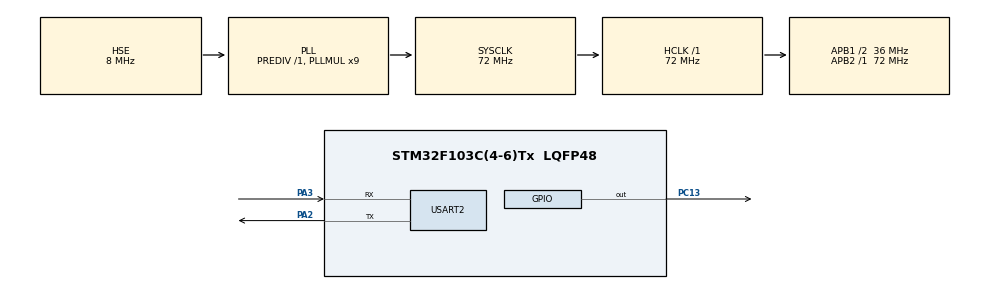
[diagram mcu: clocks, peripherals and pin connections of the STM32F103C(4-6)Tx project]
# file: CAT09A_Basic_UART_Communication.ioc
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Mcu.Family=STM32F1
Mcu.Name=STM32F103C(4-6)Tx
Mcu.Package=LQFP48
NVIC.PriorityGroup=NVIC_PRIORITYGROUP_4
PA13.Mode=Serial_Wire
PA13.Signal=SYS_JTMS-SWDIO
PA14.Mode=Serial_Wire
PA14.Signal=SYS_JTCK-SWCLK
PA2.Mode=Asynchronous
PA2.Signal=USART2_TX
PA3.Mode=Asynchronous
PA3.Signal=USART2_RX
PC13-TAMPER-RTC.Signal=GPIO_Output
PD0-OSC_IN.Mode=HSE-External-Oscillator
PD0-OSC_IN.Signal=RCC_OSC_IN
PD1-OSC_OUT.Mode=HSE-External-Oscillator
PD1-OSC_OUT.Signal=RCC_OSC_OUT
ProjectManager.HeapSize=0x200
ProjectManager.StackSize=0x400
ProjectManager.TargetToolchain=STM32CubeIDE
RCC.AHBFreq_Value=72000000
RCC.APB1CLKDivider=RCC_HCLK_DIV2
RCC.APB1Freq_Value=36000000
RCC.APB1TimFreq_Value=72000000
RCC.APB2Freq_Value=72000000
RCC.APB2TimFreq_Value=72000000
RCC.HCLKFreq_Value=72000000
RCC.PLLMUL=RCC_PLL_MUL9
RCC.PLLSourceVirtual=RCC_PLLSOURCE_HSE
RCC.SYSCLKFreq_VALUE=72000000
RCC.SYSCLKSource=RCC_SYSCLKSOURCE_PLLCLK
RCC.USBFreq_Value=72000000
USART2.VirtualMode=VM_ASYNC
board=custom

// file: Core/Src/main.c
/* USER CODE BEGIN Header */
/**
  ******************************************************************************
  * @file           : main.c
  * @brief          : CAT 9 - Task 9A : Basic UART communication (USART2, 115200-8-N-1)
  *                    Echoes every received character; sends 'A' once per second while idle.
  ******************************************************************************
  * @attention
  *
  * Copyright (c) 2026 STMicroelectronics.
  * All rights reserved.
  *
  * This software is licensed under terms that can be found in the LICENSE file
  * in the root directory of this software component.
  * If no LICENSE file comes with this software, it is provided AS-IS.
  *
  ******************************************************************************
  */
/* USER CODE END Header */
#include "main.h"

/* USER CODE BEGIN Includes */
#include <string.h>
/* USER CODE END Includes */

/* USER CODE BEGIN PD */
#define PC_UART          (&huart2)    /* USART2: PA2 = TX, PA3 = RX, 115200-8-N-1 */
#define IDLE_CHAR_MS     1000U        /* send 'A' after 1 s without input         */
/* USER CODE END PD */

UART_HandleTypeDef huart2;

/* USER CODE BEGIN PV */
static uint32_t last_activity_ms = 0;
static uint32_t chars_echoed     = 0;
/* USER CODE END PV */

void SystemClock_Config(void);
static void MX_GPIO_Init(void);
static void MX_USART2_UART_Init(void);

/* USER CODE BEGIN 0 */
static void uart_send_str(const char *s)
{
  HAL_UART_Transmit(PC_UART, (uint8_t *)s, (uint16_t)strlen(s), HAL_MAX_DELAY);
}

static void uart_send_char(uint8_t c)
{
  HAL_UART_Transmit(PC_UART, &c, 1, HAL_MAX_DELAY);
}
/* USER CODE END 0 */

int main(void)
{

  /* MCU Configuration--------------------------------------------------------*/

  /* Reset of all peripherals, Initializes the Flash interface and the Systick. */
  HAL_Init();

  /* Configure the system clock */
  SystemClock_Config();

  /* Initialize all configured peripherals */
  MX_GPIO_Init();
  MX_USART2_UART_Init();
  /* USER CODE BEGIN 2 */
  uart_send_str("\r\nCAT9A - STM32 Blue Pill UART ready (115200-8-N-1)\r\n");
  uart_send_str("Type anything: it is echoed. Idle for 1 s -> 'A' is sent.\r\n");
  last_activity_ms = HAL_GetTick();
  /* USER CODE END 2 */

  /* Infinite loop */
  while (1)
  {

    /* USER CODE BEGIN 3 */
    uint8_t rx;

    /* Receive and echo: short 10 ms timeout keeps the loop responsive */
    if (HAL_UART_Receive(PC_UART, &rx, 1, 10) == HAL_OK)
    {
      uart_send_char(rx);
      if (rx == '\r')
        uart_send_char('\n');        /* PuTTY sends only CR on Enter */
      chars_echoed++;
      last_activity_ms = HAL_GetTick();
    }
    /* Transmit a character: nothing received for 1 s -> send 'A' */
    else if ((HAL_GetTick() - last_activity_ms) >= IDLE_CHAR_MS)
    {
      uart_send_char('A');
      last_activity_ms = HAL_GetTick();
    }
  }
  /* USER CODE END 3 */
}

void SystemClock_Config(void)
{
  RCC_OscInitTypeDef RCC_OscInitStruct = {0};
  RCC_ClkInitTypeDef RCC_ClkInitStruct = {0};

  /** Initializes the RCC Oscillators according to the specified parameters
  * in the RCC_OscInitTypeDef structure.
  */
  RCC_OscInitStruct.OscillatorType = RCC_OSCILLATORTYPE_HSE;
  RCC_OscInitStruct.HSEState = RCC_HSE_ON;
  RCC_OscInitStruct.HSEPredivValue = RCC_HSE_PREDIV_DIV1;
  RCC_OscInitStruct.HSIState = RCC_HSI_ON;
  RCC_OscInitStruct.PLL.PLLState = RCC_PLL_ON;
  RCC_OscInitStruct.PLL.PLLSource = RCC_PLLSOURCE_HSE;
  RCC_OscInitStruct.PLL.PLLMUL = RCC_PLL_MUL9;
  if (HAL_RCC_OscConfig(&RCC_OscInitStruct) != HAL_OK)
  {
    Error_Handler();
  }

  /** Initializes the CPU, AHB and APB buses clocks
  */
  RCC_ClkInitStruct.ClockType = RCC_CLOCKTYPE_HCLK|RCC_CLOCKTYPE_SYSCLK
                              |RCC_CLOCKTYPE_PCLK1|RCC_CLOCKTYPE_PCLK2;
  RCC_ClkInitStruct.SYSCLKSource = RCC_SYSCLKSOURCE_PLLCLK;
  RCC_ClkInitStruct.AHBCLKDivider = RCC_SYSCLK_DIV1;
  RCC_ClkInitStruct.APB1CLKDivider = RCC_HCLK_DIV2;
  RCC_ClkInitStruct.APB2CLKDivider = RCC_HCLK_DIV1;

  if (HAL_RCC_ClockConfig(&RCC_ClkInitStruct, FLASH_LATENCY_2) != HAL_OK)
  {
    Error_Handler();
  }
}

static void MX_USART2_UART_Init(void)
{

  huart2.Instance = USART2;
  huart2.Init.BaudRate = 115200;
  huart2.Init.WordLength = UART_WORDLENGTH_8B;
  huart2.Init.StopBits = UART_STOPBITS_1;
  huart2.Init.Parity = UART_PARITY_NONE;
  huart2.Init.Mode = UART_MODE_TX_RX;
  huart2.Init.HwFlowCtl = UART_HWCONTROL_NONE;
  huart2.Init.OverSampling = UART_OVERSAMPLING_16;
  if (HAL_UART_Init(&huart2) != HAL_OK)
  {
    Error_Handler();
  }

}

static void MX_GPIO_Init(void)
{
  GPIO_InitTypeDef GPIO_InitStruct = {0};

  /* GPIO Ports Clock Enable */
  __HAL_RCC_GPIOC_CLK_ENABLE();
  __HAL_RCC_GPIOD_CLK_ENABLE();
  __HAL_RCC_GPIOA_CLK_ENABLE();

  /*Configure GPIO pin Output Level */
  HAL_GPIO_WritePin(GPIOC, GPIO_PIN_13, GPIO_PIN_RESET);

  /*Configure GPIO pin : PC13 */
  GPIO_InitStruct.Pin = GPIO_PIN_13;
  GPIO_InitStruct.Mode = GPIO_MODE_OUTPUT_PP;
  GPIO_InitStruct.Pull = GPIO_NOPULL;
  GPIO_InitStruct.Speed = GPIO_SPEED_FREQ_LOW;
  HAL_GPIO_Init(GPIOC, &GPIO_InitStruct);

}

void Error_Handler(void)
{
  __disable_irq();
  while (1)
  {
  }
}
